# ATSAMG53N19 register map
Vendor: Atmel; Series: SAMG53; File version: 0
CPU: CM4 r0p1, selectable endian, MPU, FPU, 4 interrupt priority bits
Registers are 32-bit, read-write, reset 0x0 unless marked. A register's access mark holds for its fields unless they carry their own. Offsets are from the block's base; [hi:lo] are bit positions; {n}, {i} and the like mark numbered series; 'fields as' and 'values as' point back to an identical list.

## EFC — Embedded Flash Controller
Base 0x400E0A00; register names take the prefix EFC_
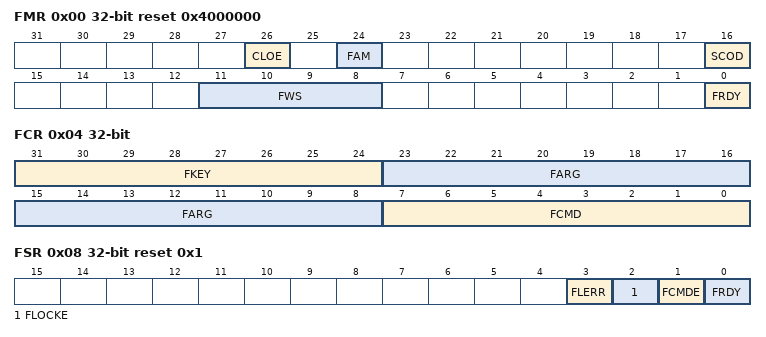
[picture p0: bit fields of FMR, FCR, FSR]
0x00 FMR reset 0x4000000 — EEFC Flash Mode Register
  [26] CLOE — Code Loop Optimization Enable
  [24] FAM — Flash Access Mode
  [16] SCOD — Sequential Code Optimization Disable
  [11:8] FWS — Flash Wait State
  [0] FRDY — Flash Ready Interrupt Enable
0x04 FCR wo reset not defined — EEFC Flash Command Register
  [31:24] FKEY — Flash Writing Protection Key
    90=PASSWD (The 0x5A value enables the command defined by the bits of the register. If the field is written with a different value, the write is not performed and no action is started.)
  [23:8] FARG — Flash Command Argument
  [7:0] FCMD — Flash Command
    0=GETD (Get Flash descriptor); 1=WP (Write page); 2=WPL (Write page and lock); 3=EWP (Erase page and write page); 4=EWPL (Erase page and write page then lock); 5=EA (Erase all); 7=EPA (Erase pages); 8=SLB (Set lock bit); 9=CLB (Clear lock bit); 10=GLB (Get lock bit); 11=SGPB (Set GPNVM bit); 12=CGPB (Clear GPNVM bit); 13=GGPB (Get GPNVM bit); 14=STUI (Start read unique identifier); 15=SPUI (Stop read unique identifier); 16=GCALB (Get CALIB bit); 17=ES (Erase sector); 18=WUS (Write user signature); 19=EUS (Erase user signature); 20=STUS (Start read user signature); 21=SPUS (Stop read user signature)
0x08 FSR ro reset 0x1 — EEFC Flash Status Register
  [3] FLERR — Flash Error Status (cleared when a programming operation starts)
  [2] FLOCKE — Flash Lock Error Status (cleared on read)
  [1] FCMDE — Flash Command Error Status (cleared on read or by writing EEFC_FCR)
  [0] FRDY — Flash Ready Status (cleared when Flash is busy)
0x0C FRR ro — EEFC Flash Result Register
  [31:0] FVALUE — Flash Result Value

## RSTC — Reset Controller
Base 0x400E1400; register names take the prefix RSTC_
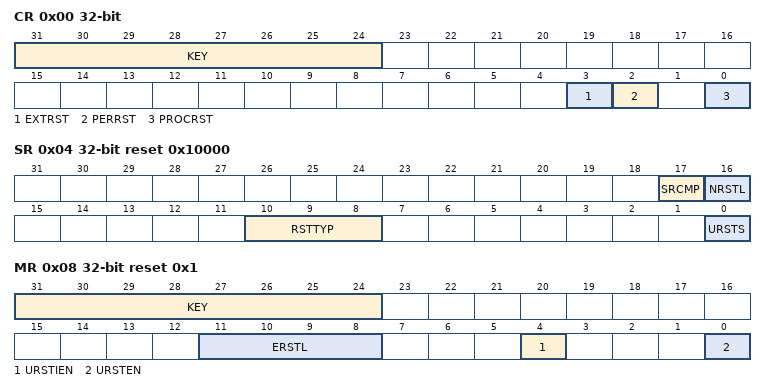
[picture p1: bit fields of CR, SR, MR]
0x00 CR wo reset not defined — Control Register
  [31:24] KEY — System Reset Key
    165=PASSWD (Writing any other value in this field aborts the write operation.)
  [3] EXTRST — External Reset
  [2] PERRST — Peripheral Reset
  [0] PROCRST — Processor Reset
0x04 SR ro reset 0x10000 — Status Register
  [17] SRCMP — Software Reset Command in Progress
  [16] NRSTL — NRST Pin Level
  [10:8] RSTTYP — Reset Type
    0=GENERAL_RST (First power-up reset); 2=WDT_RST (Watchdog fault occurred); 3=SOFT_RST (Processor reset required by the software); 4=USER_RST (NRST pin detected low)
  [0] URSTS — User Reset Status
0x08 MR reset 0x1 — Mode Register
  [31:24] KEY — Write Access Password
    165=PASSWD (Writing any other value in this field aborts the write operation.Always reads as 0.)
  [11:8] ERSTL — External Reset Length
  [4] URSTIEN — User Reset Interrupt Enable
  [0] URSTEN — User Reset Enable

## SUPC — Supply Controller
Base 0x400E1410; register names take the prefix SUPC_
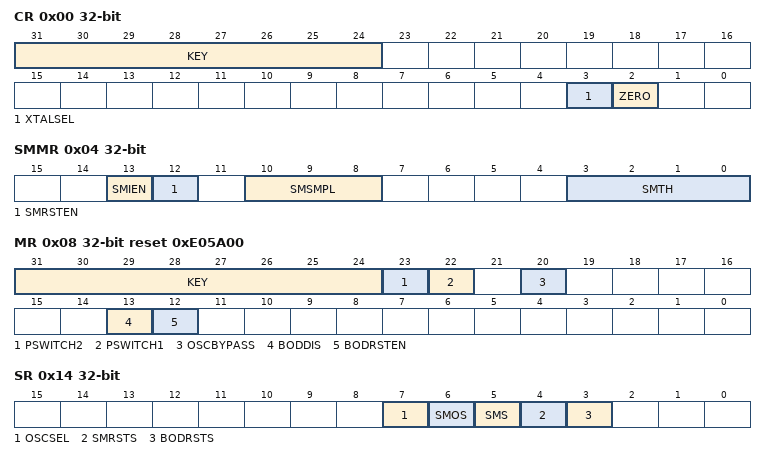
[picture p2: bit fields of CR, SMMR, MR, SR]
0x00 CR wo reset not defined — Supply Controller Control Register
  [31:24] KEY — Password
    165=PASSWD (Writing any other value in this field aborts the write operation.Always reads as 0.)
  [3] XTALSEL — Crystal Oscillator Select
    0=NO_EFFECT; 1=CRYSTAL_SEL (If KEY is correct, switches the slow clock on the crystal oscillator output.)
  [2] ZERO — This bit must always be written to 0.
0x04 SMMR — Supply Controller Supply Monitor Mode Register
  [13] SMIEN — Supply Monitor Interrupt Enable
    0=NOT_ENABLE (The SUPC interrupt signal is not affected when a supply monitor detection occurs.); 1=ENABLE (The SUPC interrupt signal is asserted when a supply monitor detection occurs.)
  [12] SMRSTEN — Supply Monitor Reset Enable
    0=NOT_ENABLE (The core reset signal vddcore_nreset is not affected when a supply monitor detection occurs.); 1=ENABLE (The core reset signal vddcore_nreset is asserted when a supply monitor detection occurs.)
  [10:8] SMSMPL — Supply Monitor Sampling Period
    0=SMD (Supply Monitor disabled); 1=CSM (Continuous Supply Monitor); 2=32SLCK (Supply Monitor enables one SLCK period every 32 SLCK periods); 3=256SLCK (Supply Monitor enables one SLCK period every 256 SLCK periods); 4=2048SLCK (Supply Monitor enables one SLCK period every 2,048 SLCK periods)
  [3:0] SMTH — Supply Monitor Threshold
0x08 MR reset 0xE05A00 — Supply Controller Mode Register
  [31:24] KEY — Password Key
    values as CR.KEY
  [23] PSWITCH2 — SRAM2 Power Switch
    0=OFF (The SRAM2 is not powered.); 1=ON (The SRAM2 is powered.)
  [22] PSWITCH1 — SRAM1 Power Switch
    0=OFF (The SRAM1 is not powered.); 1=ON (The SRAM1 is powered.)
  [20] OSCBYPASS — Oscillator Bypass
    0=NO_EFFECT (No effect. Clock selection depends on XTALSEL value.); 1=BYPASS (The 32 kHz crystal oscillator is bypassed if XTALSEL=1. OSCBYPASS must be set prior to write XTALSEL=1.)
  [13] BODDIS — POR Core Disable
    0=ENABLE (The core brownout detector is enabled.); 1=DISABLE (The core brownout detector is disabled.)
  [12] BODRSTEN — POR Core Reset Enable
    0=NOT_ENABLE (The core reset signal vddcore_nreset is not affected when a brownout detection occurs.); 1=ENABLE (The core reset signal vddcore_nreset is asserted when a brownout detection occurs.)
0x14 SR ro — Supply Controller Status Register
  [7] OSCSEL — 32-kHz Oscillator Selection Status
    0=RC (The slow clock SLCK is generated by the embedded 32 kHz RC oscillator.); 1=CRYST (The slow clock SLCK is generated by the 32 kHz crystal oscillator.)
  [6] SMOS — Supply Monitor Output Status
    0=HIGH (The supply monitor detected VDDIO higher than its threshold at its last measurement.); 1=LOW (The supply monitor detected VDDIO lower than its threshold at its last measurement.)
  [5] SMS — Supply Monitor Status (cleared on read)
    0=NO (No supply monitor detection since the last read of SUPC_SR.); 1=PRESENT (At least one supply monitor detection since the last read of SUPC_SR.)
  [4] SMRSTS — Supply Monitor Reset Status (cleared on read)
    0=NO (No supply monitor detection has generated a core reset since the last read of SUPC_SR.); 1=PRESENT (At least one supply monitor detection has generated a core reset since the last read of SUPC_SR.)
  [3] BODRSTS — Brownout Detector Reset Status (cleared on read)
    0=NO (No core brownout rising edge event has been detected since the last read of SUPC_SR.); 1=PRESENT (At least one brownout output rising edge event has been detected since the last read of SUPC_SR.)

## RTT — Real-time Timer
Base 0x400E1430; register names take the prefix RTT_
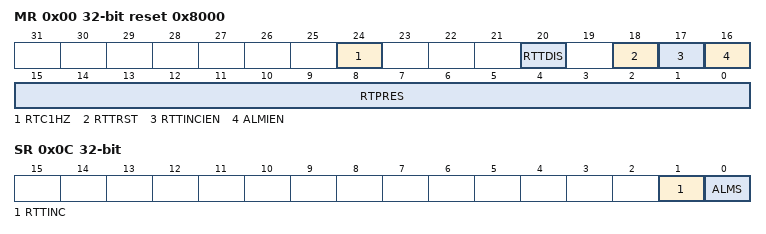
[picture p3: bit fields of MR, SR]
0x00 MR reset 0x8000 — Mode Register
  [24] RTC1HZ — Real-Time Clock 1Hz Clock Selection
  [20] RTTDIS — Real-time Timer Disable
  [18] RTTRST — Real-time Timer Restart
  [17] RTTINCIEN — Real-time Timer Increment Interrupt Enable
  [16] ALMIEN — Alarm Interrupt Enable
  [15:0] RTPRES — Real-time Timer Prescaler Value
0x04 AR reset 0xFFFFFFFF — Alarm Register
  [31:0] ALMV — Alarm Value
0x08 VR ro — Value Register
  [31:0] CRTV — Current Real-time Value
0x0C SR ro — Status Register
  [1] RTTINC — Prescaler Roll-over Status (cleared on read)
  [0] ALMS — Real-time Alarm Status (cleared on read)

## WDT — Watchdog Timer
Base 0x400E1450; register names take the prefix WDT_
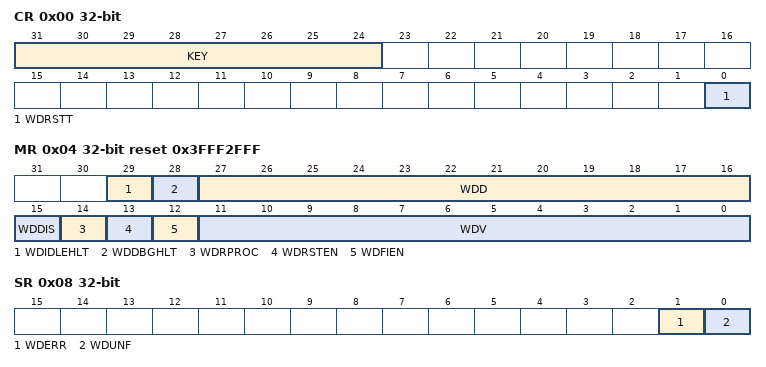
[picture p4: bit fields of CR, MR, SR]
0x00 CR wo reset not defined — Control Register
  [31:24] KEY — Password.
    165=PASSWD (Writing any other value in this field aborts the write operation.)
  [0] WDRSTT — Watchdog Restart
0x04 MR reset 0x3FFF2FFF — Mode Register
  [29] WDIDLEHLT — Watchdog Idle Halt
  [28] WDDBGHLT — Watchdog Debug Halt
  [27:16] WDD — Watchdog Delta Value
  [15] WDDIS — Watchdog Disable
  [14] WDRPROC — Watchdog Reset Processor
  [13] WDRSTEN — Watchdog Reset Enable
  [12] WDFIEN — Watchdog Fault Interrupt Enable
  [11:0] WDV — Watchdog Counter Value
0x08 SR ro — Status Register
  [1] WDERR — Watchdog Error
  [0] WDUNF — Watchdog Underflow

## GPBR — General Purpose Backup Registers
Base 0x400E1490; register names take the prefix GPBR_
{0x0+4i} GPBR[{i}] (i=0..7) reset not defined — General Purpose Backup Register
  [31:0] GPBR_VALUE — Value of GPBR x

## Notices in the file
SAM Software Package License
Copyright (c) %copyright_year%, Atmel Corporation
All rights reserved.
Redistribution and use in source and binary forms, with or without
modification, are permitted provided that the following condition is met:
- Redistributions of source code must retain the above copyright notice,
this list of conditions and the disclaimer below.
Atmel's name may not be used to endorse or promote products derived from
this software without specific prior written permission.
DISCLAIMER:  THIS SOFTWARE IS PROVIDED BY ATMEL "AS IS" AND ANY EXPRESS OR
IMPLIED WARRANTIES, INCLUDING, BUT NOT LIMITED TO, THE IMPLIED WARRANTIES OF
MERCHANTABILITY, FITNESS FOR A PARTICULAR PURPOSE AND NON-INFRINGEMENT ARE
DISCLAIMED. IN NO EVENT SHALL ATMEL BE LIABLE FOR ANY DIRECT, INDIRECT,
INCIDENTAL, SPECIAL, EXEMPLARY, OR CONSEQUENTIAL DAMAGES (INCLUDING, BUT NOT
LIMITED TO, PROCUREMENT OF SUBSTITUTE GOODS OR SERVICES; LOSS OF USE, DATA,
OR PROFITS; OR BUSINESS INTERRUPTION) HOWEVER CAUSED AND ON ANY THEORY OF
LIABILITY, WHETHER IN CONTRACT, STRICT LIABILITY, OR TORT (INCLUDING
NEGLIGENCE OR OTHERWISE) ARISING IN ANY WAY OUT OF THE USE OF THIS SOFTWARE,
EVEN IF ADVISED OF THE POSSIBILITY OF SUCH DAMAGE.
